# CBASS0_QOS register map
Vendor: Texas Instruments
Peripheral module from a debugger description file (folder am62x).
Registers are 32-bit, read-write, reset 0x7000 unless marked. A register's access mark holds for its fields unless they carry their own. Offsets are as the file gives them; lines under a group give offsets from that group; [hi:lo] are bit positions; {n}, {i} and the like mark numbered series; 'fields as' and 'values as' point back to an identical list; <NAME> marks a mode.

## CBASS0_QOS
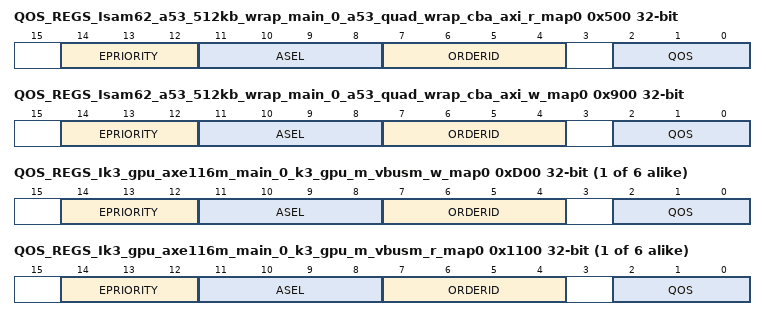
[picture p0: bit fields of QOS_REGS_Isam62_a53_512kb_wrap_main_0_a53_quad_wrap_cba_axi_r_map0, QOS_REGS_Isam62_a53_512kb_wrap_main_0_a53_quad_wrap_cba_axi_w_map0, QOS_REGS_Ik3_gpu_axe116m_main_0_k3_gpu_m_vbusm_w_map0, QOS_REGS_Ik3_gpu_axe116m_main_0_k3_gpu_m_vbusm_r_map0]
0x500 QOS_REGS_Isam62_a53_512kb_wrap_main_0_a53_quad_wrap_cba_axi_r_map0 — The Map Register defines the fields for the master Isam62_a53_512kb_wrap_main_0.a53_quad_wrap_cba_axi_r per channel.
  [14:12] EPRIORITY — epriority signal for channel N.
  [11:8] ASEL — asel signal for channel N. 0 = SOC address. 1-15 = peripheral address.
  [7:4] ORDERID — orderid signal for channel N.
  [2:0] QOS — qos signal for channel N.
0x900 QOS_REGS_Isam62_a53_512kb_wrap_main_0_a53_quad_wrap_cba_axi_w_map0 — The Map Register defines the fields for the master Isam62_a53_512kb_wrap_main_0.a53_quad_wrap_cba_axi_w per channel.
  fields as QOS_REGS_Isam62_a53_512kb_wrap_main_0_a53_quad_wrap_cba_axi_r_map0
{0xD00+4i} QOS_REGS_Ik3_gpu_axe116m_main_0_k3_gpu_m_vbusm_w_map{i} (i=0..5) — The Map Register defines the fields for the master Ik3_gpu_axe116m_main_0.k3_gpu_m_vbusm_w per channel.
  fields as QOS_REGS_Isam62_a53_512kb_wrap_main_0_a53_quad_wrap_cba_axi_r_map0
{0x1100+4i} QOS_REGS_Ik3_gpu_axe116m_main_0_k3_gpu_m_vbusm_r_map{i} (i=0..5) — The Map Register defines the fields for the master Ik3_gpu_axe116m_main_0.k3_gpu_m_vbusm_r per channel.
  fields as QOS_REGS_Isam62_a53_512kb_wrap_main_0_a53_quad_wrap_cba_axi_r_map0
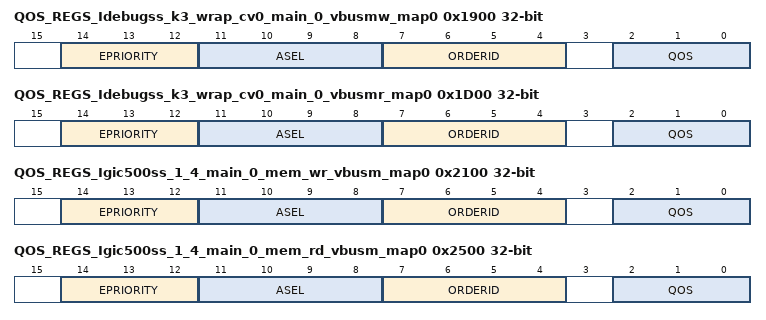
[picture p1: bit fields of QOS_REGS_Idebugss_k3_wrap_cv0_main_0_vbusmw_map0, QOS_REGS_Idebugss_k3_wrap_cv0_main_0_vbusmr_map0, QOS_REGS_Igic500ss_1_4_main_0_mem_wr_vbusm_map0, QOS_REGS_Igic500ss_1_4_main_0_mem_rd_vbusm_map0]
0x1900 QOS_REGS_Idebugss_k3_wrap_cv0_main_0_vbusmw_map0 — The Map Register defines the fields for the master Idebugss_k3_wrap_cv0_main_0.vbusmw per channel.
  fields as QOS_REGS_Isam62_a53_512kb_wrap_main_0_a53_quad_wrap_cba_axi_r_map0
0x1D00 QOS_REGS_Idebugss_k3_wrap_cv0_main_0_vbusmr_map0 — The Map Register defines the fields for the master Idebugss_k3_wrap_cv0_main_0.vbusmr per channel.
  fields as QOS_REGS_Isam62_a53_512kb_wrap_main_0_a53_quad_wrap_cba_axi_r_map0
0x2100 QOS_REGS_Igic500ss_1_4_main_0_mem_wr_vbusm_map0 — The Map Register defines the fields for the master Igic500ss_1_4_main_0.mem_wr_vbusm per channel.
  fields as QOS_REGS_Isam62_a53_512kb_wrap_main_0_a53_quad_wrap_cba_axi_r_map0
0x2500 QOS_REGS_Igic500ss_1_4_main_0_mem_rd_vbusm_map0 — The Map Register defines the fields for the master Igic500ss_1_4_main_0.mem_rd_vbusm per channel.
  fields as QOS_REGS_Isam62_a53_512kb_wrap_main_0_a53_quad_wrap_cba_axi_r_map0
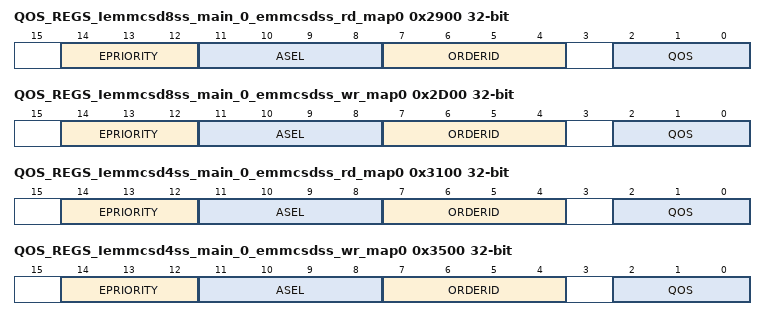
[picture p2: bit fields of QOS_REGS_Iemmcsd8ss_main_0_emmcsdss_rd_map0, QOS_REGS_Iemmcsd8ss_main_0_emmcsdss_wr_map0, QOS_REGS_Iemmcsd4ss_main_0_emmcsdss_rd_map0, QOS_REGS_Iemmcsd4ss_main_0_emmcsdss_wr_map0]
0x2900 QOS_REGS_Iemmcsd8ss_main_0_emmcsdss_rd_map0 — The Map Register defines the fields for the master Iemmcsd8ss_main_0.emmcsdss_rd per channel.
  fields as QOS_REGS_Isam62_a53_512kb_wrap_main_0_a53_quad_wrap_cba_axi_r_map0
0x2D00 QOS_REGS_Iemmcsd8ss_main_0_emmcsdss_wr_map0 — The Map Register defines the fields for the master Iemmcsd8ss_main_0.emmcsdss_wr per channel.
  fields as QOS_REGS_Isam62_a53_512kb_wrap_main_0_a53_quad_wrap_cba_axi_r_map0
0x3100 QOS_REGS_Iemmcsd4ss_main_0_emmcsdss_rd_map0 — The Map Register defines the fields for the master Iemmcsd4ss_main_0.emmcsdss_rd per channel.
  fields as QOS_REGS_Isam62_a53_512kb_wrap_main_0_a53_quad_wrap_cba_axi_r_map0
0x3500 QOS_REGS_Iemmcsd4ss_main_0_emmcsdss_wr_map0 — The Map Register defines the fields for the master Iemmcsd4ss_main_0.emmcsdss_wr per channel.
  fields as QOS_REGS_Isam62_a53_512kb_wrap_main_0_a53_quad_wrap_cba_axi_r_map0
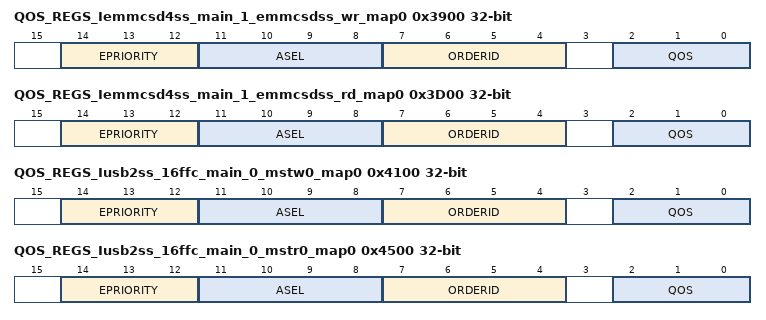
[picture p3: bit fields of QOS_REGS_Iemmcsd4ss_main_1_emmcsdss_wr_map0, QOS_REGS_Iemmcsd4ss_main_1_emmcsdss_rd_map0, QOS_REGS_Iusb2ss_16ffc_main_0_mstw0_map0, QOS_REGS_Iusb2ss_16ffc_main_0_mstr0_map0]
0x3900 QOS_REGS_Iemmcsd4ss_main_1_emmcsdss_wr_map0 — The Map Register defines the fields for the master Iemmcsd4ss_main_1.emmcsdss_wr per channel.
  fields as QOS_REGS_Isam62_a53_512kb_wrap_main_0_a53_quad_wrap_cba_axi_r_map0
0x3D00 QOS_REGS_Iemmcsd4ss_main_1_emmcsdss_rd_map0 — The Map Register defines the fields for the master Iemmcsd4ss_main_1.emmcsdss_rd per channel.
  fields as QOS_REGS_Isam62_a53_512kb_wrap_main_0_a53_quad_wrap_cba_axi_r_map0
0x4100 QOS_REGS_Iusb2ss_16ffc_main_0_mstw0_map0 — The Map Register defines the fields for the master Iusb2ss_16ffc_main_0.mstw0 per channel.
  fields as QOS_REGS_Isam62_a53_512kb_wrap_main_0_a53_quad_wrap_cba_axi_r_map0
0x4500 QOS_REGS_Iusb2ss_16ffc_main_0_mstr0_map0 — The Map Register defines the fields for the master Iusb2ss_16ffc_main_0.mstr0 per channel.
  fields as QOS_REGS_Isam62_a53_512kb_wrap_main_0_a53_quad_wrap_cba_axi_r_map0
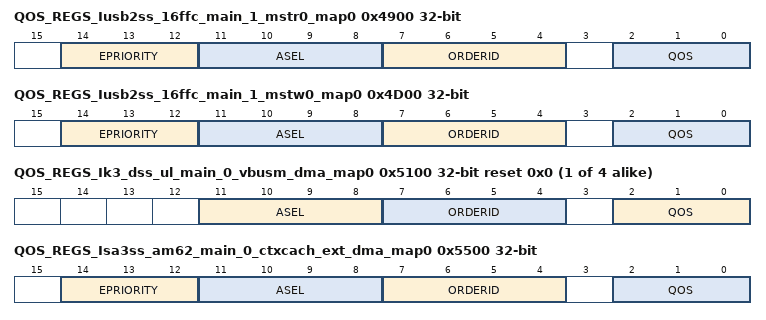
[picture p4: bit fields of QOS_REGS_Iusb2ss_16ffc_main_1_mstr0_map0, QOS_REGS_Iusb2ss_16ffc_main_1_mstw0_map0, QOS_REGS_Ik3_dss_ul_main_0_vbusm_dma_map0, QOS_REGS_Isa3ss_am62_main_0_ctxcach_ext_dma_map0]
0x4900 QOS_REGS_Iusb2ss_16ffc_main_1_mstr0_map0 — The Map Register defines the fields for the master Iusb2ss_16ffc_main_1.mstr0 per channel.
  fields as QOS_REGS_Isam62_a53_512kb_wrap_main_0_a53_quad_wrap_cba_axi_r_map0
0x4D00 QOS_REGS_Iusb2ss_16ffc_main_1_mstw0_map0 — The Map Register defines the fields for the master Iusb2ss_16ffc_main_1.mstw0 per channel.
  fields as QOS_REGS_Isam62_a53_512kb_wrap_main_0_a53_quad_wrap_cba_axi_r_map0
{0x5100+4i} QOS_REGS_Ik3_dss_ul_main_0_vbusm_dma_map{i} reset 0x0 (i=0..3) — The Map Register defines the fields for the master Ik3_dss_ul_main_0.vbusm_dma per channel.
  [11:8] ASEL — asel signal for channel N. 0 = SOC address. 1-15 = peripheral address.
  [7:4] ORDERID — orderid signal for channel N.
  [2:0] QOS — qos signal for channel N.
0x5500 QOS_REGS_Isa3ss_am62_main_0_ctxcach_ext_dma_map0 — The Map Register defines the fields for the master Isa3ss_am62_main_0.ctxcach_ext_dma per channel.
  fields as QOS_REGS_Isam62_a53_512kb_wrap_main_0_a53_quad_wrap_cba_axi_r_map0
